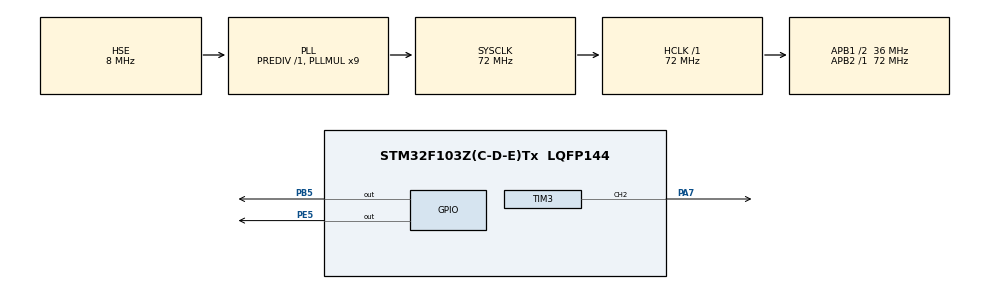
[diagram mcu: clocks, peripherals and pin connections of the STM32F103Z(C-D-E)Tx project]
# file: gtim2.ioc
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Mcu.Family=STM32F1
Mcu.Name=STM32F103Z(C-D-E)Tx
Mcu.Package=LQFP144
NVIC.PriorityGroup=NVIC_PRIORITYGROUP_4
NVIC.TIM3_IRQn=true\:0\:0\:false\:false\:true\:true\:true\:true
OSC_IN.Mode=HSE-External-Oscillator
OSC_IN.Signal=RCC_OSC_IN
OSC_OUT.Mode=HSE-External-Oscillator
OSC_OUT.Signal=RCC_OSC_OUT
PA13.Mode=Serial_Wire
PA13.Signal=SYS_JTMS-SWDIO
PA14.Mode=Serial_Wire
PA14.Signal=SYS_JTCK-SWCLK
PA7.Signal=S_TIM3_CH2
PB5.GPIO_PuPd=GPIO_PULLUP
PB5.GPIO_Speed=GPIO_SPEED_FREQ_HIGH
PB5.Signal=GPIO_Output
PC14-OSC32_IN.Mode=LSE-External-Oscillator
PC14-OSC32_IN.Signal=RCC_OSC32_IN
PC15-OSC32_OUT.Mode=LSE-External-Oscillator
PC15-OSC32_OUT.Signal=RCC_OSC32_OUT
PE5.GPIO_PuPd=GPIO_PULLUP
PE5.GPIO_Speed=GPIO_SPEED_FREQ_HIGH
PE5.Signal=GPIO_Output
ProjectManager.HeapSize=0x200
ProjectManager.StackSize=0x400
ProjectManager.TargetToolchain=CMake
RCC.AHBFreq_Value=72000000
RCC.APB1CLKDivider=RCC_HCLK_DIV2
RCC.APB1Freq_Value=36000000
RCC.APB1TimFreq_Value=72000000
RCC.APB2Freq_Value=72000000
RCC.APB2TimFreq_Value=72000000
RCC.HCLKFreq_Value=72000000
RCC.PLLMUL=RCC_PLL_MUL9
RCC.PLLSourceVirtual=RCC_PLLSOURCE_HSE
RCC.SYSCLKFreq_VALUE=72000000
RCC.SYSCLKSource=RCC_SYSCLKSOURCE_PLLCLK
RCC.USBFreq_Value=72000000
SH.S_TIM3_CH2.0=TIM3_CH2,PWM Generation2 CH2
TIM3.AutoReloadPreload=TIM_AUTORELOAD_PRELOAD_ENABLE
TIM3.Channel-PWM\ Generation2\ CH2=TIM_CHANNEL_2
TIM3.Prescaler=72
TIM3.Pulse-PWM\ Generation2\ CH2=500
VP_TIM3_VS_ClockSourceINT.Mode=Internal
board=custom

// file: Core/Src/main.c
/* USER CODE BEGIN Header */
/**
  ******************************************************************************
  * @file           : main.c
  * @brief          : Main program body
  ******************************************************************************
  * @attention
  *
  * Copyright (c) 2026 STMicroelectronics.
  * All rights reserved.
  *
  * This software is licensed under terms that can be found in the LICENSE file
  * in the root directory of this software component.
  * If no LICENSE file comes with this software, it is provided AS-IS.
  *
  ******************************************************************************
  */
/* USER CODE END Header */
#include "main.h"

TIM_HandleTypeDef htim3;

/* USER CODE BEGIN PV */
uint16_t pwm_value = 0;      // PWM占空比值(0-999)
uint16_t pwm_counter = 0;    // PWM计数器
/* USER CODE END PV */

void SystemClock_Config(void);
static void MX_GPIO_Init(void);
static void MX_TIM3_Init(void);

/* USER CODE BEGIN 0 */
// 定时器回调函数 - 用于软件PWM
void HAL_TIM_PeriodElapsedCallback(TIM_HandleTypeDef *htim)
{
  if (htim->Instance == TIM3)
  {
    pwm_counter++;
    if (pwm_counter >= 1000) {
      pwm_counter = 0;
    }

    // 根据PWM值控制LED(PE5)
    if (pwm_counter < pwm_value) {
      HAL_GPIO_WritePin(GPIOE, GPIO_PIN_5, GPIO_PIN_RESET);  // LED亮
    } else {
      HAL_GPIO_WritePin(GPIOE, GPIO_PIN_5, GPIO_PIN_SET);    // LED灭
    }
  }
}
/* USER CODE END 0 */

int main(void)
{

  /* MCU Configuration--------------------------------------------------------*/

  /* Reset of all peripherals, Initializes the Flash interface and the Systick. */
  HAL_Init();

  /* Configure the system clock */
  SystemClock_Config();

  /* Initialize all configured peripherals */
  MX_GPIO_Init();
  MX_TIM3_Init();
  /* USER CODE BEGIN 2 */
  /* 启动定时器中断用于软件PWM */
  HAL_TIM_Base_Start_IT(&htim3);
  /* USER CODE END 2 */

  /* Infinite loop */
  while (1)
  {

    /* USER CODE BEGIN 3 */
    /* 调节亮度（0-999之间） */
    pwm_value = 200;   // 20%亮度
    HAL_Delay(1000);

    pwm_value = 500;   // 50%亮度
    HAL_Delay(1000);

    pwm_value = 900;   // 90%亮度
    HAL_Delay(1000);
  }
  /* USER CODE END 3 */
}

void SystemClock_Config(void)
{
  RCC_OscInitTypeDef RCC_OscInitStruct = {0};
  RCC_ClkInitTypeDef RCC_ClkInitStruct = {0};

  /** Initializes the RCC Oscillators according to the specified parameters
  * in the RCC_OscInitTypeDef structure.
  */
  RCC_OscInitStruct.OscillatorType = RCC_OSCILLATORTYPE_HSE;
  RCC_OscInitStruct.HSEState = RCC_HSE_ON;
  RCC_OscInitStruct.HSEPredivValue = RCC_HSE_PREDIV_DIV1;
  RCC_OscInitStruct.HSIState = RCC_HSI_ON;
  RCC_OscInitStruct.PLL.PLLState = RCC_PLL_ON;
  RCC_OscInitStruct.PLL.PLLSource = RCC_PLLSOURCE_HSE;
  RCC_OscInitStruct.PLL.PLLMUL = RCC_PLL_MUL9;
  if (HAL_RCC_OscConfig(&RCC_OscInitStruct) != HAL_OK)
  {
    Error_Handler();
  }

  /** Initializes the CPU, AHB and APB buses clocks
  */
  RCC_ClkInitStruct.ClockType = RCC_CLOCKTYPE_HCLK|RCC_CLOCKTYPE_SYSCLK
                              |RCC_CLOCKTYPE_PCLK1|RCC_CLOCKTYPE_PCLK2;
  RCC_ClkInitStruct.SYSCLKSource = RCC_SYSCLKSOURCE_PLLCLK;
  RCC_ClkInitStruct.AHBCLKDivider = RCC_SYSCLK_DIV1;
  RCC_ClkInitStruct.APB1CLKDivider = RCC_HCLK_DIV2;
  RCC_ClkInitStruct.APB2CLKDivider = RCC_HCLK_DIV1;

  if (HAL_RCC_ClockConfig(&RCC_ClkInitStruct, FLASH_LATENCY_2) != HAL_OK)
  {
    Error_Handler();
  }
}

static void MX_TIM3_Init(void)
{

  TIM_ClockConfigTypeDef sClockSourceConfig = {0};
  TIM_MasterConfigTypeDef sMasterConfig = {0};
  TIM_OC_InitTypeDef sConfigOC = {0};

  htim3.Instance = TIM3;
  htim3.Init.Prescaler = 71;         // 72MHz/72 = 1MHz
  htim3.Init.CounterMode = TIM_COUNTERMODE_UP;
  htim3.Init.Period = 99;            // 1MHz/100 = 10kHz (PWM频率)
  htim3.Init.ClockDivision = TIM_CLOCKDIVISION_DIV1;
  htim3.Init.AutoReloadPreload = TIM_AUTORELOAD_PRELOAD_ENABLE;
  if (HAL_TIM_Base_Init(&htim3) != HAL_OK)
  {
    Error_Handler();
  }
  sClockSourceConfig.ClockSource = TIM_CLOCKSOURCE_INTERNAL;
  if (HAL_TIM_ConfigClockSource(&htim3, &sClockSourceConfig) != HAL_OK)
  {
    Error_Handler();
  }
  if (HAL_TIM_PWM_Init(&htim3) != HAL_OK)
  {
    Error_Handler();
  }
  sMasterConfig.MasterOutputTrigger = TIM_TRGO_RESET;
  sMasterConfig.MasterSlaveMode = TIM_MASTERSLAVEMODE_DISABLE;
  if (HAL_TIMEx_MasterConfigSynchronization(&htim3, &sMasterConfig) != HAL_OK)
  {
    Error_Handler();
  }
  sConfigOC.OCMode = TIM_OCMODE_PWM1;
  sConfigOC.Pulse = 500;
  sConfigOC.OCPolarity = TIM_OCPOLARITY_HIGH;
  sConfigOC.OCFastMode = TIM_OCFAST_DISABLE;
  if (HAL_TIM_PWM_ConfigChannel(&htim3, &sConfigOC, TIM_CHANNEL_2) != HAL_OK)
  {
    Error_Handler();
  }
  HAL_TIM_MspPostInit(&htim3);

}

static void MX_GPIO_Init(void)
{
  GPIO_InitTypeDef GPIO_InitStruct = {0};

  /* GPIO Ports Clock Enable */
  __HAL_RCC_GPIOE_CLK_ENABLE();
  __HAL_RCC_GPIOC_CLK_ENABLE();
  __HAL_RCC_GPIOA_CLK_ENABLE();
  __HAL_RCC_GPIOB_CLK_ENABLE();

  /*Configure GPIO pin Output Level */
  HAL_GPIO_WritePin(GPIOE, GPIO_PIN_5, GPIO_PIN_RESET);

  /*Configure GPIO pin Output Level */
  HAL_GPIO_WritePin(GPIOB, GPIO_PIN_5, GPIO_PIN_RESET);

  /*Configure GPIO pin : PE5 */
  GPIO_InitStruct.Pin = GPIO_PIN_5;
  GPIO_InitStruct.Mode = GPIO_MODE_OUTPUT_PP;
  GPIO_InitStruct.Pull = GPIO_PULLUP;
  GPIO_InitStruct.Speed = GPIO_SPEED_FREQ_HIGH;
  HAL_GPIO_Init(GPIOE, &GPIO_InitStruct);

  /*Configure GPIO pin : PB5 */
  GPIO_InitStruct.Pin = GPIO_PIN_5;
  GPIO_InitStruct.Mode = GPIO_MODE_OUTPUT_PP;
  GPIO_InitStruct.Pull = GPIO_PULLUP;
  GPIO_InitStruct.Speed = GPIO_SPEED_FREQ_HIGH;
  HAL_GPIO_Init(GPIOB, &GPIO_InitStruct);

}

void Error_Handler(void)
{
  __disable_irq();
  while (1)
  {
  }
}
